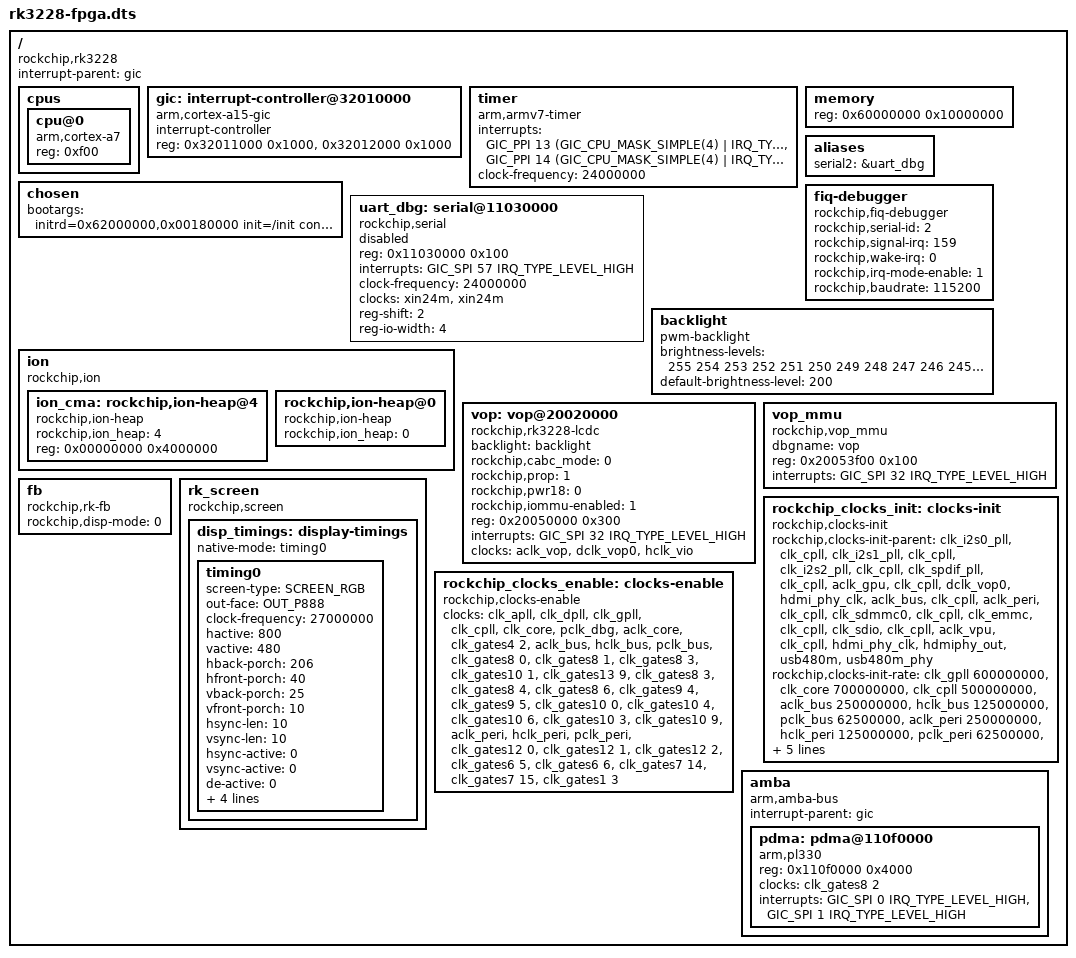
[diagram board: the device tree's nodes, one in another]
/dts-v1/;

#include <dt-bindings/interrupt-controller/arm-gic.h>
#include <dt-bindings/rkfb/rk_fb.h>

#include "skeleton.dtsi"
#include "rk3228-clocks.dtsi"

/ {
	compatible = "rockchip,rk3228";
	interrupt-parent = <&gic>;

	cpus {
		#address-cells = <1>;
		#size-cells = <0>;

		cpu@0 {
			device_type = "cpu";
			compatible = "arm,cortex-a7";
			reg = <0xf00>;
		};
	};

	gic: interrupt-controller@32010000 {
		compatible = "arm,cortex-a15-gic";
		interrupt-controller;
		#interrupt-cells = <3>;
		#address-cells = <0>;
		reg = <0x32011000 0x1000>,
		      <0x32012000 0x1000>;
	};

	timer {
		compatible = "arm,armv7-timer";
		interrupts = <GIC_PPI 13
			      (GIC_CPU_MASK_SIMPLE(4) | IRQ_TYPE_LEVEL_HIGH)>,
			     <GIC_PPI 14
			      (GIC_CPU_MASK_SIMPLE(4) | IRQ_TYPE_LEVEL_HIGH)>;
		clock-frequency = <24000000>;
	};

	memory {
		device_type = "memory";
		reg = <0x60000000 0x10000000>;
	};

	chosen {
		bootargs = "initrd=0x62000000,0x00180000 init=/init console=ttyFIQ0,115200 earlyprintk=uart8250-32bit,0x11030000";
	};

	aliases {
		serial2 = &uart_dbg;
	};

	uart_dbg: serial@11030000 {
		compatible = "rockchip,serial";
		reg = <0x11030000 0x100>;
		interrupts = <GIC_SPI 57 IRQ_TYPE_LEVEL_HIGH>;
		clock-frequency = <24000000>;
		clocks = <&xin24m>, <&xin24m>;
		clock-names = "sclk_uart", "pclk_uart";
		reg-shift = <2>;
		reg-io-width = <4>;
		status = "disabled";
	};

	fiq-debugger {
		compatible = "rockchip,fiq-debugger";
		rockchip,serial-id = <2>;
		rockchip,signal-irq = <159>;
		rockchip,wake-irq = <0>;
		rockchip,irq-mode-enable = <1>;  /* If enable uart uses irq instead of fiq */
		rockchip,baudrate = <115200>;  /* Only 115200 and 1500000 */
		//status = "disabled";
	};

        ion {
		compatible = "rockchip,ion";
		#address-cells = <1>;
		#size-cells = <0>;

		/*
		ion_carveout: rockchip,ion-heap@2 {
			compatible = "rockchip,ion-heap";
			rockchip,ion_heap = <2>;
			reg = <0x42000000 0xc00000>;
		};
			 */
		ion_cma: rockchip,ion-heap@4 {
			compatible = "rockchip,ion-heap";
			rockchip,ion_heap = <4>;
			reg = <0x00000000 0x4000000>;
		};
		rockchip,ion-heap@0 { /* VMALLOC HEAP */
			compatible = "rockchip,ion-heap";
			rockchip,ion_heap = <0>;
		};
	};

	backlight: backlight {
		compatible = "pwm-backlight";
		brightness-levels = <255 254 253 252 251 250 249 248 247 246 245 244 243 242 241 240
		     239 238 237 236 235 234 233 232 231 230 229 228 227 226 225 224 223 222 221 220
		     219 218 217 216 215 214 213 212 211 210 209 208 207 206 205 204 203 202 201 200
		     199 198 197 196 195 194 193 192 191 190 189 188 187 186 185 184 183 182 181 180
		     179 178 177 176 175 174 173 172 171 170 169 168 167 166 165 164 163 162 161 160
		     159 158 157 156 155 154 153 152 151 150 149 148 147 146 145 144 143 142 141 140
		     139 138 137 136 135 134 133 132 131 130 129 128 127 126 125 124 123 122 121 120
		     119 118 117 116 115 114 113 112 111 110 109 108 107 106 105 104 103 102 101 100
		     99 98 97 96 95 94 93 92 91 90 89 88 87 86 85 84 83 82 81 80 79 78 77 76 75 74 73 72 71 70
		     69 68 67 66 65 64 63 62 61 60 59 58 57 56 55 54 53 52 51 50 49 48 47 46 45 44 43 42 41 40
		     39 38 37 36 35 34 33 32 31 30 29 28 27 26 25 24 23 22 21 20 19 18 17 16 15 14 13 12 11 10
		     9 8 7 6 5 4 3 2 1 0>;
		default-brightness-level = <200>;
	};

	vop: vop@20020000 {
		compatible = "rockchip,rk3228-lcdc";
		backlight = <&backlight>;

		rockchip,cabc_mode = <0>;
		rockchip,prop = <1>;
		rockchip,pwr18 = <0>;
		rockchip,iommu-enabled = <1>;
		reg = <0x20050000 0x300>;
		interrupts = <GIC_SPI 32 IRQ_TYPE_LEVEL_HIGH>;
		clocks = <&aclk_vop>, <&dclk_vop0>, <&hclk_vio>;
		clock-names = "aclk_lcdc", "dclk_lcdc", "hclk_lcdc";
	};

	vop_mmu {
		dbgname = "vop";
		compatible = "rockchip,vop_mmu";
		reg = <0x20053f00 0x100>;
		interrupts = <GIC_SPI 32 IRQ_TYPE_LEVEL_HIGH>;
		interrupt-names = "vopb_mmu";
	};

	fb: fb{
		compatible = "rockchip,rk-fb";
		rockchip,disp-mode = <0>;
	};

	rk_screen: rk_screen{
		compatible = "rockchip,screen";
		disp_timings: display-timings {
                        native-mode = <&timing0>;
                        timing0: timing0 {
				screen-type = <SCREEN_RGB>;
				out-face    = <OUT_P888>;
				clock-frequency = <27000000>;
				hactive = <800>;
				vactive = <480>;
				hback-porch = <206>;
				hfront-porch = <40>;
				vback-porch = <25>;
				vfront-porch = <10>;
				hsync-len = <10>;
				vsync-len = <10>;
				hsync-active = <0>;
				vsync-active = <0>;
				de-active = <0>;
				pixelclk-active = <0>;
				swap-rb = <0>;
				swap-rg = <0>;
				swap-gb = <0>;
			};
		};
	};

	rockchip_clocks_init: clocks-init{
		compatible = "rockchip,clocks-init";
		rockchip,clocks-init-parent =
			<&clk_i2s0_pll &clk_cpll>, <&clk_i2s1_pll &clk_cpll>,
			<&clk_i2s2_pll &clk_cpll>, <&clk_spdif_pll &clk_cpll>,
			<&aclk_gpu &clk_cpll>, <&dclk_vop0 &hdmi_phy_clk>,
			<&aclk_bus &clk_cpll>, <&aclk_peri &clk_cpll>,
			<&clk_sdmmc0 &clk_cpll>, <&clk_emmc &clk_cpll>,
			<&clk_sdio &clk_cpll>, <&aclk_vpu &clk_cpll>,
			<&hdmi_phy_clk &hdmiphy_out>, <&usb480m &usb480m_phy>;
		rockchip,clocks-init-rate =
			<&clk_gpll 600000000>, <&clk_core 700000000>,
			<&clk_cpll 500000000>, <&aclk_bus 250000000>,
			<&hclk_bus 125000000>, <&pclk_bus 62500000>,
			<&aclk_peri 250000000>, <&hclk_peri 125000000>,
			<&pclk_peri 62500000>, <&clk_mac 125000000>,
			<&aclk_iep 250000000>, <&hclk_vio 125000000>,
			<&aclk_rga 250000000>, <&aclk_gpu 250000000>,
			<&aclk_vpu 25000000>, <&clk_vdec_core 250000000>,
			<&clk_vdec_cabac 250000000>;
/*
		rockchip,clocks-uboot-has-init =
			<&aclk_vio0>;
*/
	};

	rockchip_clocks_enable: clocks-enable {
		compatible = "rockchip,clocks-enable";
		clocks =
			/*PLL*/
			<&clk_apll>,
			<&clk_dpll>,
			<&clk_gpll>,
			<&clk_cpll>,

			/*PD_CORE*/
			<&clk_core>,
			<&pclk_dbg>,
			<&aclk_core>,
			<&clk_gates4 2>,

			/*PD_BUS*/
			<&aclk_bus>,
			<&hclk_bus>,
			<&pclk_bus>,
			<&clk_gates8 0>,/*aclk_intmem*/
			<&clk_gates8 1>,/*clk_intmem_mbist*/
			<&clk_gates8 3>,/*aclk_dmac_bus*/
			<&clk_gates10 1>,/*g_aclk_bus*/
			<&clk_gates13 9>,/*aclk_gic400*/
			<&clk_gates8 3>,/*hclk_rom*/
			<&clk_gates8 4>,/*pclk_ddrupctl*/
			<&clk_gates8 6>,/*pclk_ddrmon*/
			<&clk_gates9 4>,/*pclk_timer0*/
			<&clk_gates9 5>,/*pclk_stimer*/
			<&clk_gates10 0>,/*pclk_grf*/
			<&clk_gates10 4>,/*pclk_cru*/
			<&clk_gates10 6>,/*pclk_sgrf*/
			<&clk_gates10 3>,/*pclk_ddrphy*/
			<&clk_gates10 9>,/*pclk_phy_noc*/

			/*PD_PERI*/
			<&aclk_peri>,
			<&hclk_peri>,
			<&pclk_peri>,
			<&clk_gates12 0>,/*aclk_peri_noc*/
			<&clk_gates12 1>,/*hclk_peri_noc*/
			<&clk_gates12 2>,/*pclk_peri_noc*/

			<&clk_gates6 5>, /* g_clk_timer0 */
			<&clk_gates6 6>, /* g_clk_timer1 */

			<&clk_gates7 14>, /* g_aclk_gpu */
			<&clk_gates7 15>, /* g_aclk_gpu_noc */

			<&clk_gates1 3>;/*clk_jtag*/
	};

	amba {
		#address-cells = <1>;
		#size-cells = <1>;
		compatible = "arm,amba-bus";
		interrupt-parent = <&gic>;
		ranges;

		pdma: pdma@110f0000 {
			compatible = "arm,pl330", "arm,primecell";
			reg = <0x110f0000 0x4000>;
			clocks = <&clk_gates8 2>;
			clock-names = "apb_pclk";
			interrupts = <GIC_SPI 0 IRQ_TYPE_LEVEL_HIGH>,
				     <GIC_SPI 1 IRQ_TYPE_LEVEL_HIGH>;
			#dma-cells = <1>;
		};
	};
};
